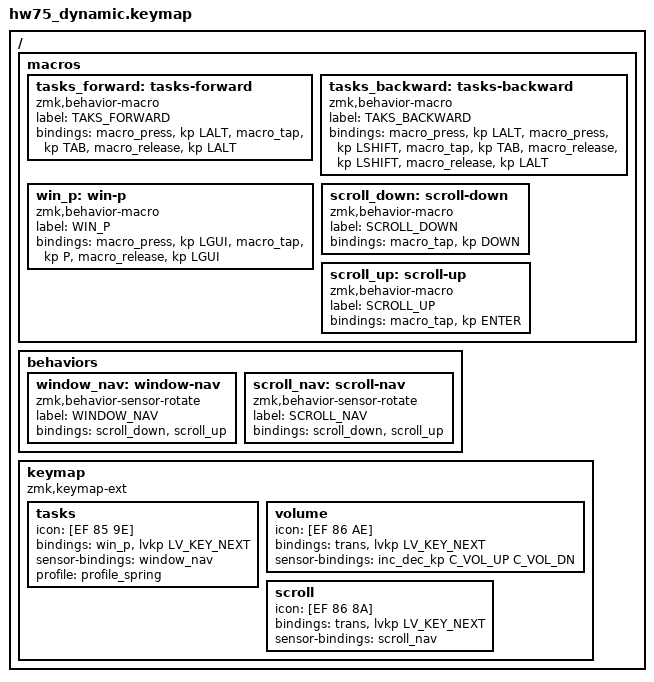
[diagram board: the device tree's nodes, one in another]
/*
 * Copyright (c) 2022 The ZMK Contributors
 * SPDX-License-Identifier: MIT
 */

#include <behaviors.dtsi>
#include <behaviors/lvgl_key_press.dtsi>
#include <behaviors/sensor_rotate_mouse_wheel.dtsi>
#include <dt-bindings/zmk/keys.h>
#include <dt-bindings/zmk/rgb.h>
#include <dt-bindings/zmk/lvgl.h>
#include <dt-bindings/zmk/mouse.h>

/ {
	macros {
		tasks_forward: tasks-forward {
			label = "TAKS_FORWARD";
			compatible = "zmk,behavior-macro";
			#binding-cells = <0>;
			bindings = <&macro_press   &kp LALT>,
				   <&macro_tap     &kp TAB>,
				   <&macro_release &kp LALT>;
		};

		tasks_backward: tasks-backward {
			label = "TAKS_BACKWARD";
			compatible = "zmk,behavior-macro";
			#binding-cells = <0>;
			bindings = <&macro_press   &kp LALT>,
				   <&macro_press   &kp LSHIFT>,
				   <&macro_tap     &kp TAB>,
				   <&macro_release &kp LSHIFT>,
				   <&macro_release &kp LALT>;
		};

		win_p: win-p {
			label = "WIN_P";
			compatible = "zmk,behavior-macro";
			#binding-cells = <0>;
			bindings = <&macro_press   &kp LGUI>,
				   <&macro_tap     &kp P>,
				   <&macro_release &kp LGUI>;
		};

		scroll_down: scroll-down {
			label = "SCROLL_DOWN";
			compatible = "zmk,behavior-macro";
			#binding-cells = <0>;
			bindings = <&macro_tap     &kp DOWN>;
		};

		scroll_up: scroll-up {
			label = "SCROLL_UP";
			compatible = "zmk,behavior-macro";
			#binding-cells = <0>;
			bindings = <&macro_tap     &kp ENTER>;
		};
	};

	behaviors {
		window_nav: window-nav {
			compatible = "zmk,behavior-sensor-rotate";
			label = "WINDOW_NAV";
			#sensor-binding-cells = <0>;
			bindings = <&scroll_down>, <&scroll_up>;
		};

		scroll_nav: scroll-nav {
			compatible = "zmk,behavior-sensor-rotate";
			label = "SCROLL_NAV";
			#sensor-binding-cells = <0>;
			bindings = <&scroll_down>, <&scroll_up>;
		};
	};

	keymap {
		compatible = "zmk,keymap-ext", "zmk,keymap";

	tasks {
		label = "窗口";
		icon = [EF 85 9E];
		bindings = <&win_p &lvkp LV_KEY_NEXT>;
		sensor-bindings = <&window_nav>;
		profile = <&profile_spring>;
	};

	volume {
		label = "音量";
		icon = [EF 86 AE];
		bindings = <&trans &lvkp LV_KEY_NEXT>;
		sensor-bindings = <&inc_dec_kp C_VOL_UP C_VOL_DN>;
	};

	scroll {
		label = "滚动";
		icon = [EF 86 8A];
		bindings = <&trans &lvkp LV_KEY_NEXT>;
		sensor-bindings = <&scroll_nav>;
	};
	};
};
